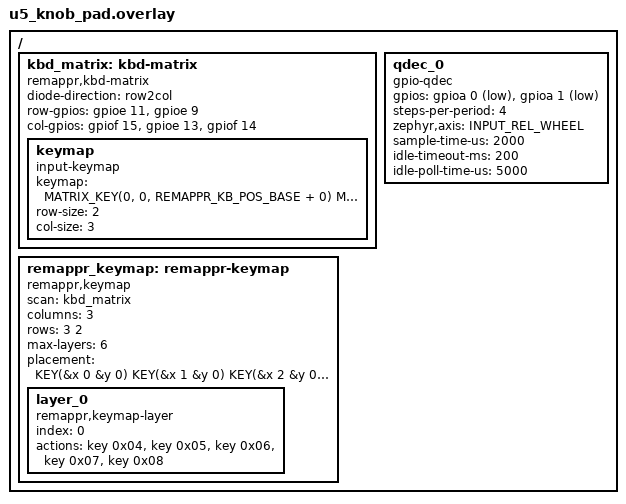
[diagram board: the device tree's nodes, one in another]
/*
 * U5 Knob Pad — Remappr shield (generated by remappr).
 *
 * Drop this directory into a remappr-firmware checkout under
 * boards/shields/u5_knob_pad/ and build with -DSHIELD=u5_knob_pad. Verify the
 * row/col GPIO specs against your wiring — remappr derives the matrix
 * cells from physical key position, not the electrical matrix.
 *
 * SPDX-License-Identifier: Apache-2.0
 */

#include <zephyr/dt-bindings/input/input-event-codes.h>
#include <zephyr/dt-bindings/input/keymap.h>
#include <dt-bindings/remappr/keys.h>
#include <dt-bindings/remappr/layout.h>
#include <remappr/keymap-tokens.dtsi>
#include <remappr/behavior-tokens.dtsi>

/ {
	kbd_matrix: kbd-matrix {
		compatible = "remappr,kbd-matrix";
		diode-direction = "row2col";
		row-gpios =
			<&gpioe 11 GPIO_ACTIVE_HIGH>,
			<&gpioe 9 GPIO_ACTIVE_HIGH>;
		col-gpios =
			<&gpiof 15 (GPIO_ACTIVE_HIGH | GPIO_PULL_DOWN)>,
			<&gpioe 13 (GPIO_ACTIVE_HIGH | GPIO_PULL_DOWN)>,
			<&gpiof 14 (GPIO_ACTIVE_HIGH | GPIO_PULL_DOWN)>;

		keymap {
			compatible = "input-keymap";
			keymap = <
				MATRIX_KEY(0, 0, REMAPPR_KB_POS_BASE + 0) MATRIX_KEY(0, 1, REMAPPR_KB_POS_BASE + 1) MATRIX_KEY(0, 2, REMAPPR_KB_POS_BASE + 2)
				MATRIX_KEY(1, 0, REMAPPR_KB_POS_BASE + 3) MATRIX_KEY(1, 1, REMAPPR_KB_POS_BASE + 4)
			>;
			row-size = <2>;
			col-size = <3>;
		};
	};

	remappr_keymap: remappr-keymap {
		compatible = "remappr,keymap";
		scan = <&kbd_matrix>;
		columns = <3>;
		rows = <3 2>;
		max-layers = <6>;
		placement = <
				KEY(&x 0 &y 0) KEY(&x 1 &y 0) KEY(&x 2 &y 0)
				KEY(&x 0 &y 1 &w 2) KEY(&x 3 &y 1 &rot 345 &rotx 3 &roty 1)
		>;
		layer_0 {
			compatible = "remappr,keymap-layer";
			index = <0>;
			actions = <
				&key 0x04 &key 0x05 &key 0x06
				&key 0x07 &key 0x08
			>;
		};
	};
};

/ {
	qdec_0: qdec_0 {
		compatible = "gpio-qdec";
		gpios = <&gpioa 0 (GPIO_ACTIVE_LOW | GPIO_PULL_UP)>, <&gpioa 1 (GPIO_ACTIVE_LOW | GPIO_PULL_UP)>;
		steps-per-period = <4>;
		zephyr,axis = <INPUT_REL_WHEEL>;
		sample-time-us = <2000>;
		idle-timeout-ms = <200>;
		idle-poll-time-us = <5000>;
	};
};
